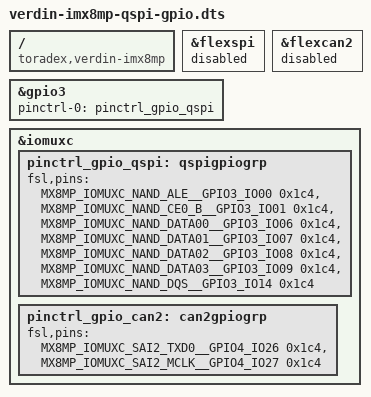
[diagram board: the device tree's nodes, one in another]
/dts-v1/;
/plugin/;

#include "../dt-bindings/gpio/gpio.h"
#include "imx8mp-pinfunc.h"

/ {
	compatible = "toradex,verdin-imx8mp";
};

&flexspi {
	status = "disabled";
};

&flexcan2 {
	status = "disabled";
};

&gpio3 {
	pinctrl-names = "default";
	pinctrl-0 = <&pinctrl_gpio_qspi>;
};

&iomuxc {
	pinctrl_gpio_qspi: qspigpiogrp {
		fsl,pins =
			<MX8MP_IOMUXC_NAND_ALE__GPIO3_IO00		0x1c4>,	// GPIO_SODIMM_52	GPIO3_IO0	ALT5
			<MX8MP_IOMUXC_NAND_CE0_B__GPIO3_IO01	0x1c4>,	// GPIO_SODIMM_54	GPIO3_IO1	ALT5
			<MX8MP_IOMUXC_NAND_DATA00__GPIO3_IO06	0x1c4>,	// GPIO_SODIMM_56	GPIO3_IO6	ALT5
			<MX8MP_IOMUXC_NAND_DATA01__GPIO3_IO07	0x1c4>,	// GPIO_SODIMM_58	GPIO3_IO7	ALT5
			<MX8MP_IOMUXC_NAND_DATA02__GPIO3_IO08	0x1c4>,	// GPIO_SODIMM_60	GPIO3_IO8	ALT5
			<MX8MP_IOMUXC_NAND_DATA03__GPIO3_IO09	0x1c4>,	// GPIO_SODIMM_62	GPIO3_IO9	ALT5
			<MX8MP_IOMUXC_NAND_DQS__GPIO3_IO14		0x1c4>;	// GPIO_SODIMM_66	GPIO3_IO14	ALT5
	};

	pinctrl_gpio_can2: can2gpiogrp {
		fsl,pins =
			<MX8MP_IOMUXC_SAI2_TXD0__GPIO4_IO26		0x1c4>,	// GPIO_SODIMM_24	GPIO3_IO26	ALT5
			<MX8MP_IOMUXC_SAI2_MCLK__GPIO4_IO27		0x1c4>;	// GPIO_SODIMM_26	GPIO3_IO27	ALT5
	};
};
